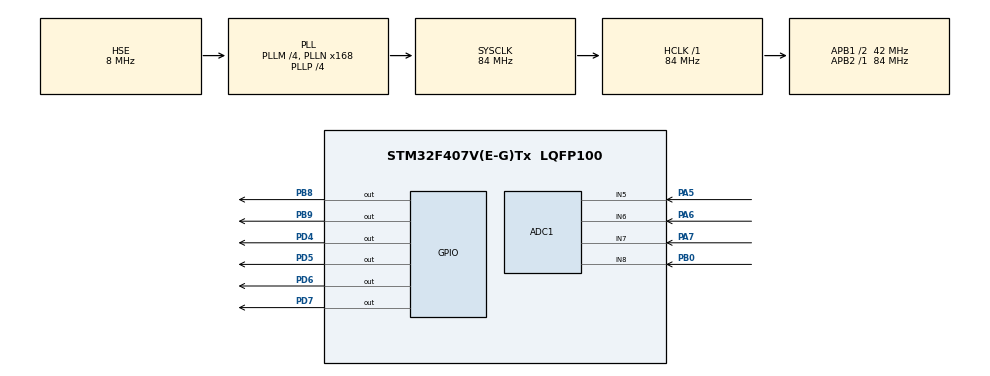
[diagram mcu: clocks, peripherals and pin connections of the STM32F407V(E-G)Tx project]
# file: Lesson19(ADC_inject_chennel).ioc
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ADC1.Channel-0\#ChannelRegularConversion=ADC_CHANNEL_5
ADC1.Channel-1\#ChannelInjectedConversion=ADC_CHANNEL_5
ADC1.Channel-2\#ChannelInjectedConversion=ADC_CHANNEL_6
ADC1.Channel-3\#ChannelInjectedConversion=ADC_CHANNEL_7
ADC1.Channel-4\#ChannelInjectedConversion=ADC_CHANNEL_8
ADC1.InjNumberOfConversion=4
ADC1.InjectedOffset-1\#ChannelInjectedConversion=0
ADC1.InjectedOffset-2\#ChannelInjectedConversion=0
ADC1.InjectedOffset-3\#ChannelInjectedConversion=0
ADC1.InjectedOffset-4\#ChannelInjectedConversion=0
ADC1.NbrOfConversionFlag=1
ADC1.Rank-0\#ChannelRegularConversion=1
ADC1.Rank-1\#ChannelInjectedConversion=1
ADC1.Rank-2\#ChannelInjectedConversion=2
ADC1.Rank-3\#ChannelInjectedConversion=3
ADC1.Rank-4\#ChannelInjectedConversion=4
ADC1.SamplingTime-0\#ChannelRegularConversion=ADC_SAMPLETIME_3CYCLES
ADC1.SamplingTime-1\#ChannelInjectedConversion=ADC_SAMPLETIME_3CYCLES
ADC1.SamplingTime-2\#ChannelInjectedConversion=ADC_SAMPLETIME_3CYCLES
ADC1.SamplingTime-3\#ChannelInjectedConversion=ADC_SAMPLETIME_3CYCLES
ADC1.SamplingTime-4\#ChannelInjectedConversion=ADC_SAMPLETIME_3CYCLES
ADC1.ScanConvMode=ENABLE
ADC1.master=1
Mcu.Family=STM32F4
Mcu.Name=STM32F407V(E-G)Tx
Mcu.Package=LQFP100
NVIC.PriorityGroup=NVIC_PRIORITYGROUP_4
PA5.Signal=ADCx_IN5
PA6.Signal=ADCx_IN6
PA7.Signal=ADCx_IN7
PB0.Signal=ADCx_IN8
PB8.Signal=GPIO_Output
PB9.Signal=GPIO_Output
PD4.Signal=GPIO_Output
PD5.Signal=GPIO_Output
PD6.Signal=GPIO_Output
PD7.Signal=GPIO_Output
PH0-OSC_IN.Mode=HSE-External-Oscillator
PH0-OSC_IN.Signal=RCC_OSC_IN
PH1-OSC_OUT.Mode=HSE-External-Oscillator
PH1-OSC_OUT.Signal=RCC_OSC_OUT
ProjectManager.HeapSize=0x200
ProjectManager.StackSize=0x400
ProjectManager.TargetToolchain=MDK-ARM V5
RCC.48MHZClocksFreq_Value=84000000
RCC.AHBFreq_Value=84000000
RCC.APB1CLKDivider=RCC_HCLK_DIV2
RCC.APB1Freq_Value=42000000
RCC.APB1TimFreq_Value=84000000
RCC.APB2Freq_Value=84000000
RCC.APB2TimFreq_Value=84000000
RCC.CortexFreq_Value=84000000
RCC.HCLKFreq_Value=84000000
RCC.HSE_VALUE=8000000
RCC.HSI_VALUE=16000000
RCC.LSE_VALUE=32768
RCC.PLLM=4
RCC.PLLN=168
RCC.PLLP=RCC_PLLP_DIV4
RCC.PLLSourceVirtual=RCC_PLLSOURCE_HSE
RCC.SYSCLKFreq_VALUE=84000000
RCC.SYSCLKSource=RCC_SYSCLKSOURCE_PLLCLK
RCC.VCOOutputFreq_Value=336000000
SH.ADCx_IN5.0=ADC1_IN5,IN5
SH.ADCx_IN6.0=ADC1_IN6,IN6
SH.ADCx_IN7.0=ADC1_IN7,IN7
SH.ADCx_IN8.0=ADC1_IN8,IN8
board=Lesson19(ADC_inject_chennel)

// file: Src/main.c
/**
  ******************************************************************************
  * File Name          : main.c
  * Description        : Main program body
  ******************************************************************************
  *
  * COPYRIGHT(c) 2017 STMicroelectronics
  *
  * Redistribution and use in source and binary forms, with or without modification,
  * are permitted provided that the following conditions are met:
  *   1. Redistributions of source code must retain the above copyright notice,
  *      this list of conditions and the following disclaimer.
  *   2. Redistributions in binary form must reproduce the above copyright notice,
  *      this list of conditions and the following disclaimer in the documentation
  *      and/or other materials provided with the distribution.
  *   3. Neither the name of STMicroelectronics nor the names of its contributors
  *      may be used to endorse or promote products derived from this software
  *      without specific prior written permission.
  *
  * THIS SOFTWARE IS PROVIDED BY THE COPYRIGHT HOLDERS AND CONTRIBUTORS "AS IS"
  * AND ANY EXPRESS OR IMPLIED WARRANTIES, INCLUDING, BUT NOT LIMITED TO, THE
  * IMPLIED WARRANTIES OF MERCHANTABILITY AND FITNESS FOR A PARTICULAR PURPOSE ARE
  * DISCLAIMED. IN NO EVENT SHALL THE COPYRIGHT HOLDER OR CONTRIBUTORS BE LIABLE
  * FOR ANY DIRECT, INDIRECT, INCIDENTAL, SPECIAL, EXEMPLARY, OR CONSEQUENTIAL
  * DAMAGES (INCLUDING, BUT NOT LIMITED TO, PROCUREMENT OF SUBSTITUTE GOODS OR
  * SERVICES; LOSS OF USE, DATA, OR PROFITS; OR BUSINESS INTERRUPTION) HOWEVER
  * CAUSED AND ON ANY THEORY OF LIABILITY, WHETHER IN CONTRACT, STRICT LIABILITY,
  * OR TORT (INCLUDING NEGLIGENCE OR OTHERWISE) ARISING IN ANY WAY OUT OF THE USE
  * OF THIS SOFTWARE, EVEN IF ADVISED OF THE POSSIBILITY OF SUCH DAMAGE.
  *
  ******************************************************************************
  */
#include "main.h"
#include "stm32f4xx_hal.h"
#include <string.h>

ADC_HandleTypeDef hadc1;

/* USER CODE BEGIN PV */
/* Private variables ---------------------------------------------------------*/
volatile uint16_t ADC_Data[4];

/* USER CODE END PV */

void SystemClock_Config(void);
void Error_Handler(void);
static void MX_GPIO_Init(void);
static void MX_ADC1_Init(void);

int main(void)
{
float voltage[4];
	char str[21];
	char str1[9];

  /* MCU Configuration----------------------------------------------------------*/

  /* Reset of all peripherals, Initializes the Flash interface and the Systick. */
  HAL_Init();

  /* Configure the system clock */
  SystemClock_Config();

  /* Initialize all configured peripherals */
  MX_GPIO_Init();
  MX_ADC1_Init();
	LCD_ini();
  /* USER CODE BEGIN 2 */
	LCD_GOTOXY(0,0);
	LCD_printstring("Hello User!!!");

  while (1)
  {
		HAL_ADCEx_InjectedStart(&hadc1);

    HAL_ADC_PollForConversion(&hadc1,100);//дождёмся окончания преобразований
		voltage[0]=((float)HAL_ADCEx_InjectedGetValue(&hadc1,ADC_INJECTED_RANK_1))*3/4096;
		voltage[1]=((float)HAL_ADCEx_InjectedGetValue(&hadc1,ADC_INJECTED_RANK_2))*3/4096;
		voltage[2]=((float)HAL_ADCEx_InjectedGetValue(&hadc1,ADC_INJECTED_RANK_3))*3/4096;
		voltage[3]=((float)HAL_ADCEx_InjectedGetValue(&hadc1,ADC_INJECTED_RANK_4))*3/4096;

		HAL_ADCEx_InjectedStop(&hadc1);

		sprintf(str,"%.2fv",voltage[0]);//преобразуем результат в строку
		sprintf(str1,"%.2fv",voltage[1]);//преобразуем результат в строку

		strcat(str,str1);

		sprintf(str,"%.2fv",voltage[2]);//преобразуем результат в строку
		sprintf(str1,"%.2fv",voltage[3]);//преобразуем результат в строку

		strcat(str,str1);
		 LCD_GOTOXY(0,1);//покажем результат на ЖКИ-дисплее
     LCD_printstring(str);
			HAL_Delay(200);

  }
  /* USER CODE END 3 */

}

/** System Clock Configuration
*/
void SystemClock_Config(void)
{

  RCC_OscInitTypeDef RCC_OscInitStruct;
  RCC_ClkInitTypeDef RCC_ClkInitStruct;

    /**Configure the main internal regulator output voltage
    */
  __HAL_RCC_PWR_CLK_ENABLE();

  __HAL_PWR_VOLTAGESCALING_CONFIG(PWR_REGULATOR_VOLTAGE_SCALE1);

    /**Initializes the CPU, AHB and APB busses clocks
    */
  RCC_OscInitStruct.OscillatorType = RCC_OSCILLATORTYPE_HSE;
  RCC_OscInitStruct.HSEState = RCC_HSE_ON;
  RCC_OscInitStruct.PLL.PLLState = RCC_PLL_ON;
  RCC_OscInitStruct.PLL.PLLSource = RCC_PLLSOURCE_HSE;
  RCC_OscInitStruct.PLL.PLLM = 4;
  RCC_OscInitStruct.PLL.PLLN = 168;
  RCC_OscInitStruct.PLL.PLLP = RCC_PLLP_DIV4;
  RCC_OscInitStruct.PLL.PLLQ = 4;
  if (HAL_RCC_OscConfig(&RCC_OscInitStruct) != HAL_OK)
  {
    Error_Handler();
  }

    /**Initializes the CPU, AHB and APB busses clocks
    */
  RCC_ClkInitStruct.ClockType = RCC_CLOCKTYPE_HCLK|RCC_CLOCKTYPE_SYSCLK
                              |RCC_CLOCKTYPE_PCLK1|RCC_CLOCKTYPE_PCLK2;
  RCC_ClkInitStruct.SYSCLKSource = RCC_SYSCLKSOURCE_PLLCLK;
  RCC_ClkInitStruct.AHBCLKDivider = RCC_SYSCLK_DIV1;
  RCC_ClkInitStruct.APB1CLKDivider = RCC_HCLK_DIV2;
  RCC_ClkInitStruct.APB2CLKDivider = RCC_HCLK_DIV1;

  if (HAL_RCC_ClockConfig(&RCC_ClkInitStruct, FLASH_LATENCY_2) != HAL_OK)
  {
    Error_Handler();
  }

    /**Configure the Systick interrupt time
    */
  HAL_SYSTICK_Config(HAL_RCC_GetHCLKFreq()/1000);

    /**Configure the Systick
    */
  HAL_SYSTICK_CLKSourceConfig(SYSTICK_CLKSOURCE_HCLK);

  /* SysTick_IRQn interrupt configuration */
  HAL_NVIC_SetPriority(SysTick_IRQn, 0, 0);
}

/* ADC1 init function */
static void MX_ADC1_Init(void)
{

  ADC_ChannelConfTypeDef sConfig;
  ADC_InjectionConfTypeDef sConfigInjected;

    /**Configure the global features of the ADC (Clock, Resolution, Data Alignment and number of conversion)
    */
  hadc1.Instance = ADC1;
  hadc1.Init.ClockPrescaler = ADC_CLOCK_SYNC_PCLK_DIV4;
  hadc1.Init.Resolution = ADC_RESOLUTION_12B;
  hadc1.Init.ScanConvMode = ENABLE;
  hadc1.Init.ContinuousConvMode = DISABLE;
  hadc1.Init.DiscontinuousConvMode = DISABLE;
  hadc1.Init.ExternalTrigConvEdge = ADC_EXTERNALTRIGCONVEDGE_NONE;
  hadc1.Init.ExternalTrigConv = ADC_SOFTWARE_START;
  hadc1.Init.DataAlign = ADC_DATAALIGN_RIGHT;
  hadc1.Init.NbrOfConversion = 1;
  hadc1.Init.DMAContinuousRequests = DISABLE;
  hadc1.Init.EOCSelection = ADC_EOC_SINGLE_CONV;
  if (HAL_ADC_Init(&hadc1) != HAL_OK)
  {
    Error_Handler();
  }

    /**Configure for the selected ADC regular channel its corresponding rank in the sequencer and its sample time.
    */
  sConfig.Channel = ADC_CHANNEL_5;
  sConfig.Rank = 1;
  sConfig.SamplingTime = ADC_SAMPLETIME_3CYCLES;
  if (HAL_ADC_ConfigChannel(&hadc1, &sConfig) != HAL_OK)
  {
    Error_Handler();
  }

    /**Configures for the selected ADC injected channel its corresponding rank in the sequencer and its sample time
    */
  sConfigInjected.InjectedChannel = ADC_CHANNEL_5;
  sConfigInjected.InjectedRank = 1;
  sConfigInjected.InjectedNbrOfConversion = 4;
  sConfigInjected.InjectedSamplingTime = ADC_SAMPLETIME_3CYCLES;
  sConfigInjected.ExternalTrigInjecConvEdge = ADC_EXTERNALTRIGINJECCONVEDGE_NONE;
  sConfigInjected.ExternalTrigInjecConv = ADC_INJECTED_SOFTWARE_START;
  sConfigInjected.AutoInjectedConv = DISABLE;
  sConfigInjected.InjectedDiscontinuousConvMode = DISABLE;
  sConfigInjected.InjectedOffset = 0;
  if (HAL_ADCEx_InjectedConfigChannel(&hadc1, &sConfigInjected) != HAL_OK)
  {
    Error_Handler();
  }

    /**Configures for the selected ADC injected channel its corresponding rank in the sequencer and its sample time
    */
  sConfigInjected.InjectedChannel = ADC_CHANNEL_6;
  sConfigInjected.InjectedRank = 2;
  if (HAL_ADCEx_InjectedConfigChannel(&hadc1, &sConfigInjected) != HAL_OK)
  {
    Error_Handler();
  }

    /**Configures for the selected ADC injected channel its corresponding rank in the sequencer and its sample time
    */
  sConfigInjected.InjectedChannel = ADC_CHANNEL_7;
  sConfigInjected.InjectedRank = 3;
  if (HAL_ADCEx_InjectedConfigChannel(&hadc1, &sConfigInjected) != HAL_OK)
  {
    Error_Handler();
  }

    /**Configures for the selected ADC injected channel its corresponding rank in the sequencer and its sample time
    */
  sConfigInjected.InjectedChannel = ADC_CHANNEL_8;
  sConfigInjected.InjectedRank = 4;
  if (HAL_ADCEx_InjectedConfigChannel(&hadc1, &sConfigInjected) != HAL_OK)
  {
    Error_Handler();
  }

}

/** Configure pins as
        * Analog
        * Input
        * Output
        * EVENT_OUT
        * EXTI
*/
static void MX_GPIO_Init(void)
{

  GPIO_InitTypeDef GPIO_InitStruct;

  /* GPIO Ports Clock Enable */
  __HAL_RCC_GPIOH_CLK_ENABLE();
  __HAL_RCC_GPIOA_CLK_ENABLE();
  __HAL_RCC_GPIOB_CLK_ENABLE();
  __HAL_RCC_GPIOD_CLK_ENABLE();

  /*Configure GPIO pin Output Level */
  HAL_GPIO_WritePin(GPIOD, GPIO_PIN_4|GPIO_PIN_5|GPIO_PIN_6|GPIO_PIN_7, GPIO_PIN_RESET);

  /*Configure GPIO pin Output Level */
  HAL_GPIO_WritePin(GPIOB, GPIO_PIN_8|GPIO_PIN_9, GPIO_PIN_RESET);

  /*Configure GPIO pins : PD4 PD5 PD6 PD7 */
  GPIO_InitStruct.Pin = GPIO_PIN_4|GPIO_PIN_5|GPIO_PIN_6|GPIO_PIN_7;
  GPIO_InitStruct.Mode = GPIO_MODE_OUTPUT_PP;
  GPIO_InitStruct.Pull = GPIO_NOPULL;
  GPIO_InitStruct.Speed = GPIO_SPEED_FREQ_LOW;
  HAL_GPIO_Init(GPIOD, &GPIO_InitStruct);

  /*Configure GPIO pins : PB8 PB9 */
  GPIO_InitStruct.Pin = GPIO_PIN_8|GPIO_PIN_9;
  GPIO_InitStruct.Mode = GPIO_MODE_OUTPUT_PP;
  GPIO_InitStruct.Pull = GPIO_NOPULL;
  GPIO_InitStruct.Speed = GPIO_SPEED_FREQ_LOW;
  HAL_GPIO_Init(GPIOB, &GPIO_InitStruct);

}

void Error_Handler(void)
{
  while(1)
  {
  }
}

/************************ (C) COPYRIGHT STMicroelectronics *****END OF FILE****/
